AUTOSAR XML (schema 4-0-3)
package /ComponentTypes
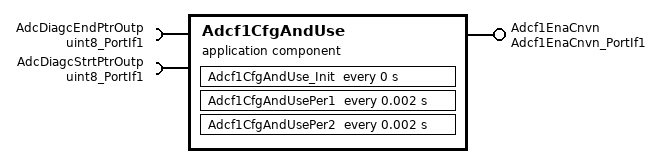
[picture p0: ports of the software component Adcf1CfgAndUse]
  application sw component type Adcf1CfgAndUse
    provide port Adcf1EnaCnvn: server-com-spec{operation=Oper, queue-length=1}, provided-interface=Adcf1EnaCnvn_PortIf1
    require port AdcDiagcEndPtrOutp: nonqueued-receiver-com-spec{data-element=Val, filter=data-filter-type=ALWAYS, init-value=23}, required-interface=uint8_PortIf1
    require port AdcDiagcStrtPtrOutp: nonqueued-receiver-com-spec{data-element=Val, filter=data-filter-type=ALWAYS, init-value=21}, required-interface=uint8_PortIf1
    behavior Adcf1CfgAndUse_InternalBehavior
      ar-typed-per-instance-memorys:
        data Adcf1DiagcEndPtr: sw-calibration-access=READ-ONLY, type=uint8
        data Adcf1DiagcStrtPtr: sw-calibration-access=READ-ONLY, type=uint8
      timing event Adcf1CfgAndUse_InitEvent: start-on-event=Adcf1CfgAndUse_Init, period=0
      timing event TMT_Adcf1CfgAndUsePer1: start-on-event=Adcf1CfgAndUsePer1, period=0.002
      timing event TMT_Adcf1CfgAndUsePer2: start-on-event=Adcf1CfgAndUsePer2, period=0.002
      operation invoked event OIT_Adcf1EnaCnvn_Oper_Adcf1EnaCnvn_Oper: start-on-event=Adcf1EnaCnvn_Oper, operation=Adcf1EnaCnvn.Oper
      4 x runnable:
        Adcf1CfgAndUse_Init
        Adcf1CfgAndUsePer1
        Adcf1CfgAndUsePer2
          data-receive-point-by-arguments:
            access REC_AdcDiagcEndPtrOutp_Val: accessed-variable=AdcDiagcEndPtrOutp.Val
            access REC_AdcDiagcStrtPtrOutp_Val: accessed-variable=AdcDiagcStrtPtrOutp.Val
        Adcf1EnaCnvn_Oper
  swc implementation Adcf1CfgAndUse_Implementation: behavior=Adcf1CfgAndUse_InternalBehavior
    code-descriptors:
      code Default: artifact-descriptors=autosar-engineering-object={short-label=Default, category=SWSRC}
